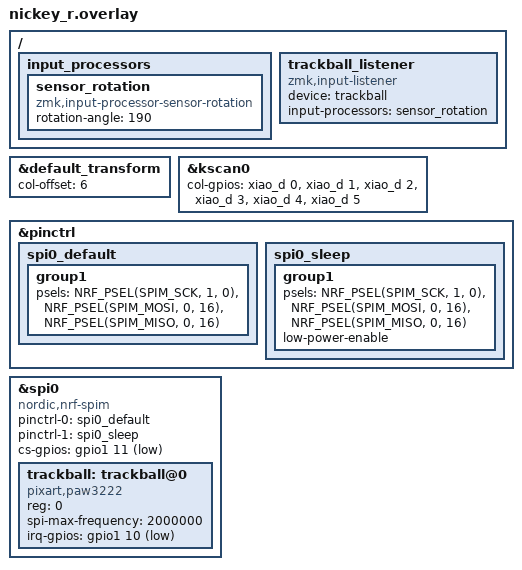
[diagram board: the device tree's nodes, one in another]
#include "nickey.dtsi"
#include <input/processors.dtsi>
#include <zephyr/dt-bindings/input/input-event-codes.h>
#include "input/processors/sensor_rotation.dtsi"

&default_transform {
    col-offset = <6>;
};

&kscan0 {
        col-gpios
            = <&xiao_d 0 GPIO_ACTIVE_HIGH>
            , <&xiao_d 1 GPIO_ACTIVE_HIGH>
            , <&xiao_d 2 GPIO_ACTIVE_HIGH>
            , <&xiao_d 3 GPIO_ACTIVE_HIGH>
            , <&xiao_d 4 GPIO_ACTIVE_HIGH>
            , <&xiao_d 5 GPIO_ACTIVE_HIGH>
            ;
};

&pinctrl {
    spi0_default: spi0_default {
        group1 {
            psels = <NRF_PSEL(SPIM_SCK, 1, 0)>,
                <NRF_PSEL(SPIM_MOSI, 0, 16)>,
                <NRF_PSEL(SPIM_MISO, 0, 16)>;
        };
    };

    spi0_sleep: spi0_sleep {
        group1 {
            psels = <NRF_PSEL(SPIM_SCK, 1, 0)>,
                <NRF_PSEL(SPIM_MOSI, 0, 16)>,
                <NRF_PSEL(SPIM_MISO, 0, 16)>;
            low-power-enable;
        };
    };
};

&spi0 {
    status = "okay";
    compatible = "nordic,nrf-spim";
    pinctrl-0 = <&spi0_default>;
    pinctrl-1 = <&spi0_sleep>;
    pinctrl-names = "default", "sleep";
    cs-gpios = <&gpio1 11 GPIO_ACTIVE_LOW>;

    trackball: trackball@0 {
        status = "okay";
        compatible = "pixart,paw3222";
        reg = <0>;
        spi-max-frequency = <2000000>;
        irq-gpios = <&gpio1 10 GPIO_ACTIVE_LOW>;
    };
};

/ {
    input_processors {
        sensor_rotation: sensor_rotation {
            compatible = "zmk,input-processor-sensor-rotation";
            #input-processor-cells = <0>;
			rotation-angle = <190>;
        };
    };
    trackball_listener {
        compatible = "zmk,input-listener";
        device = <&trackball>;
        input-processors = <&sensor_rotation>;
    };
};
